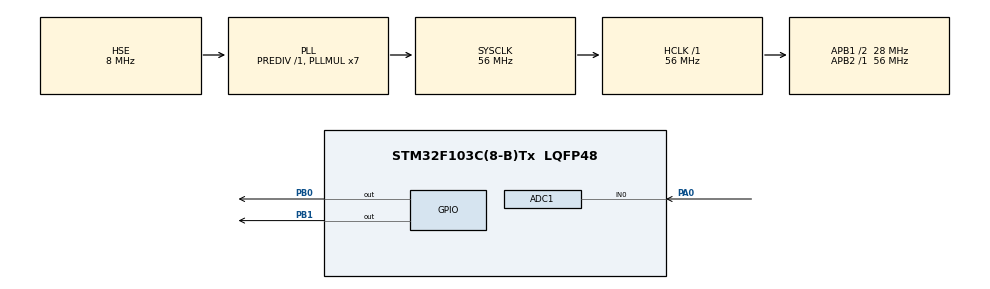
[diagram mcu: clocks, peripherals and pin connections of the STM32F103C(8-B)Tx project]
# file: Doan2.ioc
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ADC1.Channel-1\#ChannelRegularConversion=ADC_CHANNEL_0
ADC1.NbrOfConversionFlag=1
ADC1.Rank-1\#ChannelRegularConversion=1
ADC1.SamplingTime-1\#ChannelRegularConversion=ADC_SAMPLETIME_1CYCLE_5
ADC1.master=1
FREERTOS.Tasks01=Task1,2,128,TaskPWM,Default,NULL,Dynamic,NULL,NULL;Task2,-2,128,TaskDisplay,Default,NULL,Dynamic,NULL,NULL
Mcu.Family=STM32F1
Mcu.Name=STM32F103C(8-B)Tx
Mcu.Package=LQFP48
NVIC.PriorityGroup=NVIC_PRIORITYGROUP_4
NVIC.TIM1_UP_IRQn=true\:15\:0\:false\:false\:true\:false\:false\:true\:true
NVIC.TimeBase=TIM1_UP_IRQn
NVIC.TimeBaseIP=TIM1
PA0-WKUP.Signal=ADCx_IN0
PA13.Mode=Serial_Wire
PA13.Signal=SYS_JTMS-SWDIO
PA14.Mode=Serial_Wire
PA14.Signal=SYS_JTCK-SWCLK
PB0.GPIO_Speed=GPIO_SPEED_FREQ_HIGH
PB0.Signal=GPIO_Output
PB1.GPIO_Speed=GPIO_SPEED_FREQ_HIGH
PB1.Signal=GPIO_Output
PC14-OSC32_IN.Mode=LSE-External-Oscillator
PC14-OSC32_IN.Signal=RCC_OSC32_IN
PC15-OSC32_OUT.Mode=LSE-External-Oscillator
PC15-OSC32_OUT.Signal=RCC_OSC32_OUT
PD0-OSC_IN.Mode=HSE-External-Oscillator
PD0-OSC_IN.Signal=RCC_OSC_IN
PD1-OSC_OUT.Mode=HSE-External-Oscillator
PD1-OSC_OUT.Signal=RCC_OSC_OUT
ProjectManager.HeapSize=0x200
ProjectManager.StackSize=0x400
ProjectManager.TargetToolchain=MDK-ARM V5.32
RCC.ADCPresc=RCC_ADCPCLK2_DIV4
RCC.AHBFreq_Value=56000000
RCC.APB1CLKDivider=RCC_HCLK_DIV2
RCC.APB1Freq_Value=28000000
RCC.APB1TimFreq_Value=56000000
RCC.APB2Freq_Value=56000000
RCC.APB2TimFreq_Value=56000000
RCC.HCLKFreq_Value=56000000
RCC.PLLMUL=RCC_PLL_MUL7
RCC.PLLSourceVirtual=RCC_PLLSOURCE_HSE
RCC.SYSCLKFreq_VALUE=56000000
RCC.SYSCLKSource=RCC_SYSCLKSOURCE_PLLCLK
RCC.USBFreq_Value=56000000
SH.ADCx_IN0.0=ADC1_IN0,IN0
TIM2.Prescaler=55
VP_FREERTOS_VS_CMSIS_V1.Mode=CMSIS_V1
VP_SYS_VS_tim1.Mode=TIM1
VP_TIM2_VS_ClockSourceINT.Mode=Internal
board=custom

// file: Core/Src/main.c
/* USER CODE BEGIN Header */
/**
  ******************************************************************************
  * @file           : main.c
  * @brief          : Main program body
  ******************************************************************************
  * @attention
  *
  * Copyright (c) 2022 STMicroelectronics.
  * All rights reserved.
  *
  * This software is licensed under terms that can be found in the LICENSE file
  * in the root directory of this software component.
  * If no LICENSE file comes with this software, it is provided AS-IS.
  *
  ******************************************************************************
  */
/* USER CODE END Header */
#include "main.h"
#include "cmsis_os.h"
#include "lcd16x2.h"

ADC_HandleTypeDef hadc1;

TIM_HandleTypeDef htim2;

osThreadId Task1Handle;
osThreadId Task2Handle;
/* USER CODE BEGIN PV */
uint16_t value[]={0,10,19,29,38,47,56,63,71,77,83,88,92,96,98,100,100,100,98,96,92,88,83,77,71,64,56,47,38,29,20,10,0};
#define t_cycle 312
// declare variable temp using task delay
uint16_t temp=0;
uint32_t var;
float voltage;
uint16_t natural,remain;
/* USER CODE END PV */

void SystemClock_Config(void);
static void MX_GPIO_Init(void);
static void MX_TIM2_Init(void);
static void MX_ADC1_Init(void);
void TaskPWM(void const * argument);
void TaskDisplay(void const * argument);

/* USER CODE BEGIN PFP */
void Delay_TIM_us(TIM_HandleTypeDef *htim, uint16_t time);
void Delay_TIM_Ms(TIM_HandleTypeDef *htim, uint16_t time);
/* USER CODE END PFP */

int main(void)
{

  /* MCU Configuration--------------------------------------------------------*/

  /* Reset of all peripherals, Initializes the Flash interface and the Systick. */
  HAL_Init();

  /* Configure the system clock */
  SystemClock_Config();

  /* Initialize all configured peripherals */
  MX_GPIO_Init();
  MX_TIM2_Init();
  MX_ADC1_Init();
  /* USER CODE BEGIN 2 */
	HAL_TIM_Base_Start(&htim2);
  LCD_Init();
  /* USER CODE END 2 */

  /* Create the thread(s) */
  /* definition and creation of Task1 */
  osThreadDef(Task1, TaskPWM, osPriorityHigh, 0, 128);
  Task1Handle = osThreadCreate(osThread(Task1), NULL);

  /* definition and creation of Task2 */
  osThreadDef(Task2, TaskDisplay, osPriorityLow, 0, 128);
  Task2Handle = osThreadCreate(osThread(Task2), NULL);

  /* Start scheduler */
  osKernelStart();

  /* We should never get here as control is now taken by the scheduler */
  /* Infinite loop */
  while (1)
  {

  }
}

void SystemClock_Config(void)
{
  RCC_OscInitTypeDef RCC_OscInitStruct = {0};
  RCC_ClkInitTypeDef RCC_ClkInitStruct = {0};
  RCC_PeriphCLKInitTypeDef PeriphClkInit = {0};

  /** Initializes the RCC Oscillators according to the specified parameters
  * in the RCC_OscInitTypeDef structure.
  */
  RCC_OscInitStruct.OscillatorType = RCC_OSCILLATORTYPE_HSE;
  RCC_OscInitStruct.HSEState = RCC_HSE_ON;
  RCC_OscInitStruct.HSEPredivValue = RCC_HSE_PREDIV_DIV1;
  RCC_OscInitStruct.HSIState = RCC_HSI_ON;
  RCC_OscInitStruct.PLL.PLLState = RCC_PLL_ON;
  RCC_OscInitStruct.PLL.PLLSource = RCC_PLLSOURCE_HSE;
  RCC_OscInitStruct.PLL.PLLMUL = RCC_PLL_MUL7;
  if (HAL_RCC_OscConfig(&RCC_OscInitStruct) != HAL_OK)
  {
    Error_Handler();
  }

  /** Initializes the CPU, AHB and APB buses clocks
  */
  RCC_ClkInitStruct.ClockType = RCC_CLOCKTYPE_HCLK|RCC_CLOCKTYPE_SYSCLK
                              |RCC_CLOCKTYPE_PCLK1|RCC_CLOCKTYPE_PCLK2;
  RCC_ClkInitStruct.SYSCLKSource = RCC_SYSCLKSOURCE_PLLCLK;
  RCC_ClkInitStruct.AHBCLKDivider = RCC_SYSCLK_DIV1;
  RCC_ClkInitStruct.APB1CLKDivider = RCC_HCLK_DIV2;
  RCC_ClkInitStruct.APB2CLKDivider = RCC_HCLK_DIV1;

  if (HAL_RCC_ClockConfig(&RCC_ClkInitStruct, FLASH_LATENCY_2) != HAL_OK)
  {
    Error_Handler();
  }
  PeriphClkInit.PeriphClockSelection = RCC_PERIPHCLK_ADC;
  PeriphClkInit.AdcClockSelection = RCC_ADCPCLK2_DIV4;
  if (HAL_RCCEx_PeriphCLKConfig(&PeriphClkInit) != HAL_OK)
  {
    Error_Handler();
  }
}

static void MX_ADC1_Init(void)
{

  ADC_ChannelConfTypeDef sConfig = {0};

  /** Common config
  */
  hadc1.Instance = ADC1;
  hadc1.Init.ScanConvMode = ADC_SCAN_DISABLE;
  hadc1.Init.ContinuousConvMode = DISABLE;
  hadc1.Init.DiscontinuousConvMode = DISABLE;
  hadc1.Init.ExternalTrigConv = ADC_SOFTWARE_START;
  hadc1.Init.DataAlign = ADC_DATAALIGN_RIGHT;
  hadc1.Init.NbrOfConversion = 1;
  if (HAL_ADC_Init(&hadc1) != HAL_OK)
  {
    Error_Handler();
  }

  /** Configure Regular Channel
  */
  sConfig.Channel = ADC_CHANNEL_0;
  sConfig.Rank = ADC_REGULAR_RANK_1;
  sConfig.SamplingTime = ADC_SAMPLETIME_1CYCLE_5;
  if (HAL_ADC_ConfigChannel(&hadc1, &sConfig) != HAL_OK)
  {
    Error_Handler();
  }

}

static void MX_TIM2_Init(void)
{

  TIM_ClockConfigTypeDef sClockSourceConfig = {0};
  TIM_MasterConfigTypeDef sMasterConfig = {0};

  htim2.Instance = TIM2;
  htim2.Init.Prescaler = 55;
  htim2.Init.CounterMode = TIM_COUNTERMODE_UP;
  htim2.Init.Period = 65535;
  htim2.Init.ClockDivision = TIM_CLOCKDIVISION_DIV1;
  htim2.Init.AutoReloadPreload = TIM_AUTORELOAD_PRELOAD_DISABLE;
  if (HAL_TIM_Base_Init(&htim2) != HAL_OK)
  {
    Error_Handler();
  }
  sClockSourceConfig.ClockSource = TIM_CLOCKSOURCE_INTERNAL;
  if (HAL_TIM_ConfigClockSource(&htim2, &sClockSourceConfig) != HAL_OK)
  {
    Error_Handler();
  }
  sMasterConfig.MasterOutputTrigger = TIM_TRGO_RESET;
  sMasterConfig.MasterSlaveMode = TIM_MASTERSLAVEMODE_DISABLE;
  if (HAL_TIMEx_MasterConfigSynchronization(&htim2, &sMasterConfig) != HAL_OK)
  {
    Error_Handler();
  }

}

static void MX_GPIO_Init(void)
{
  GPIO_InitTypeDef GPIO_InitStruct = {0};

  /* GPIO Ports Clock Enable */
  __HAL_RCC_GPIOC_CLK_ENABLE();
  __HAL_RCC_GPIOD_CLK_ENABLE();
  __HAL_RCC_GPIOA_CLK_ENABLE();
  __HAL_RCC_GPIOB_CLK_ENABLE();

  /*Configure GPIO pin Output Level */
  HAL_GPIO_WritePin(GPIOB, GPIO_PIN_0|GPIO_PIN_1, GPIO_PIN_RESET);

  /*Configure GPIO pins : PB0 PB1 */
  GPIO_InitStruct.Pin = GPIO_PIN_0|GPIO_PIN_1;
  GPIO_InitStruct.Mode = GPIO_MODE_OUTPUT_PP;
  GPIO_InitStruct.Pull = GPIO_NOPULL;
  GPIO_InitStruct.Speed = GPIO_SPEED_FREQ_HIGH;
  HAL_GPIO_Init(GPIOB, &GPIO_InitStruct);

}

/* USER CODE BEGIN 4 */
// function delay_us
void Delay_TIM_us(TIM_HandleTypeDef *htim, uint16_t time)
{
	__HAL_TIM_SET_COUNTER(htim,0);
	while(__HAL_TIM_GET_COUNTER(htim)<time) {}
}

// function delay_ms
void Delay_TIM_Ms(TIM_HandleTypeDef *htim, uint16_t time)
{
	__HAL_TIM_SetCounter(htim,0);
	while(time--)
	{
		__HAL_TIM_SetCounter(htim,0);
		while(__HAL_TIM_GetCounter(htim)<1000)
		{
		}
	}
}

// function PWM_duty
void PWM_duty(GPIO_TypeDef *GPIOx, uint16_t GPIO_Pin,unsigned int duty)
{
	int value=t_cycle*duty/100;
	HAL_GPIO_WritePin(GPIOx,GPIO_Pin,0);
	Delay_TIM_us(&htim2,value);
	HAL_GPIO_WritePin(GPIOx,GPIO_Pin,1);
	Delay_TIM_us(&htim2,t_cycle-value);
}
/* USER CODE END 4 */

void TaskPWM(void const * argument)
{
  /* USER CODE BEGIN 5 */
  /* Infinite loop */
  for(;;)
  {
		uint16_t i;
		for(i=0;i<15;i++)
		{
			PWM_duty(GPIOB,GPIO_PIN_0,value[i]);
		}
    osDelay(1);
		for(i=18;i<32;i++)
		{
			PWM_duty(GPIOB,GPIO_PIN_0,value[i]);
		}
		for(i=0;i<15;i++)
		{
			PWM_duty(GPIOB,GPIO_PIN_1,value[i]);
		}
    osDelay(1);
		for(i=18;i<32;i++)
		{
			PWM_duty(GPIOB,GPIO_PIN_1,value[i]);
		}
  }
  /* USER CODE END 5 */
}

void TaskDisplay(void const * argument)
{
  /* USER CODE BEGIN TaskDisplay */
  /* Infinite loop */
  for(;;)
  {
		if (temp==0)
		{
			HAL_ADC_Start(&hadc1);
			var=HAL_ADC_GetValue(&hadc1);
			// Vref=3.3V, ADC: 12 bit
			voltage = var*3.3/4096;
			HAL_ADC_Stop(&hadc1);
			temp=1;
		}
		else
		{
		natural=(int)voltage;
		remain=voltage-natural;
		LCD_Puts("Dien ap bang");
	  LCD_PutChar(natural/10+48);
		LCD_PutChar(natural%10+48);
		LCD_PutChar((int)remain/0.1+48);
		temp=0;
		}
    osDelay(10000);
  }
  /* USER CODE END TaskDisplay */
}

void HAL_TIM_PeriodElapsedCallback(TIM_HandleTypeDef *htim)
{
  if (htim->Instance == TIM1) {
    HAL_IncTick();
  }
}

void Error_Handler(void)
{
  __disable_irq();
  while (1)
  {
  }
}
